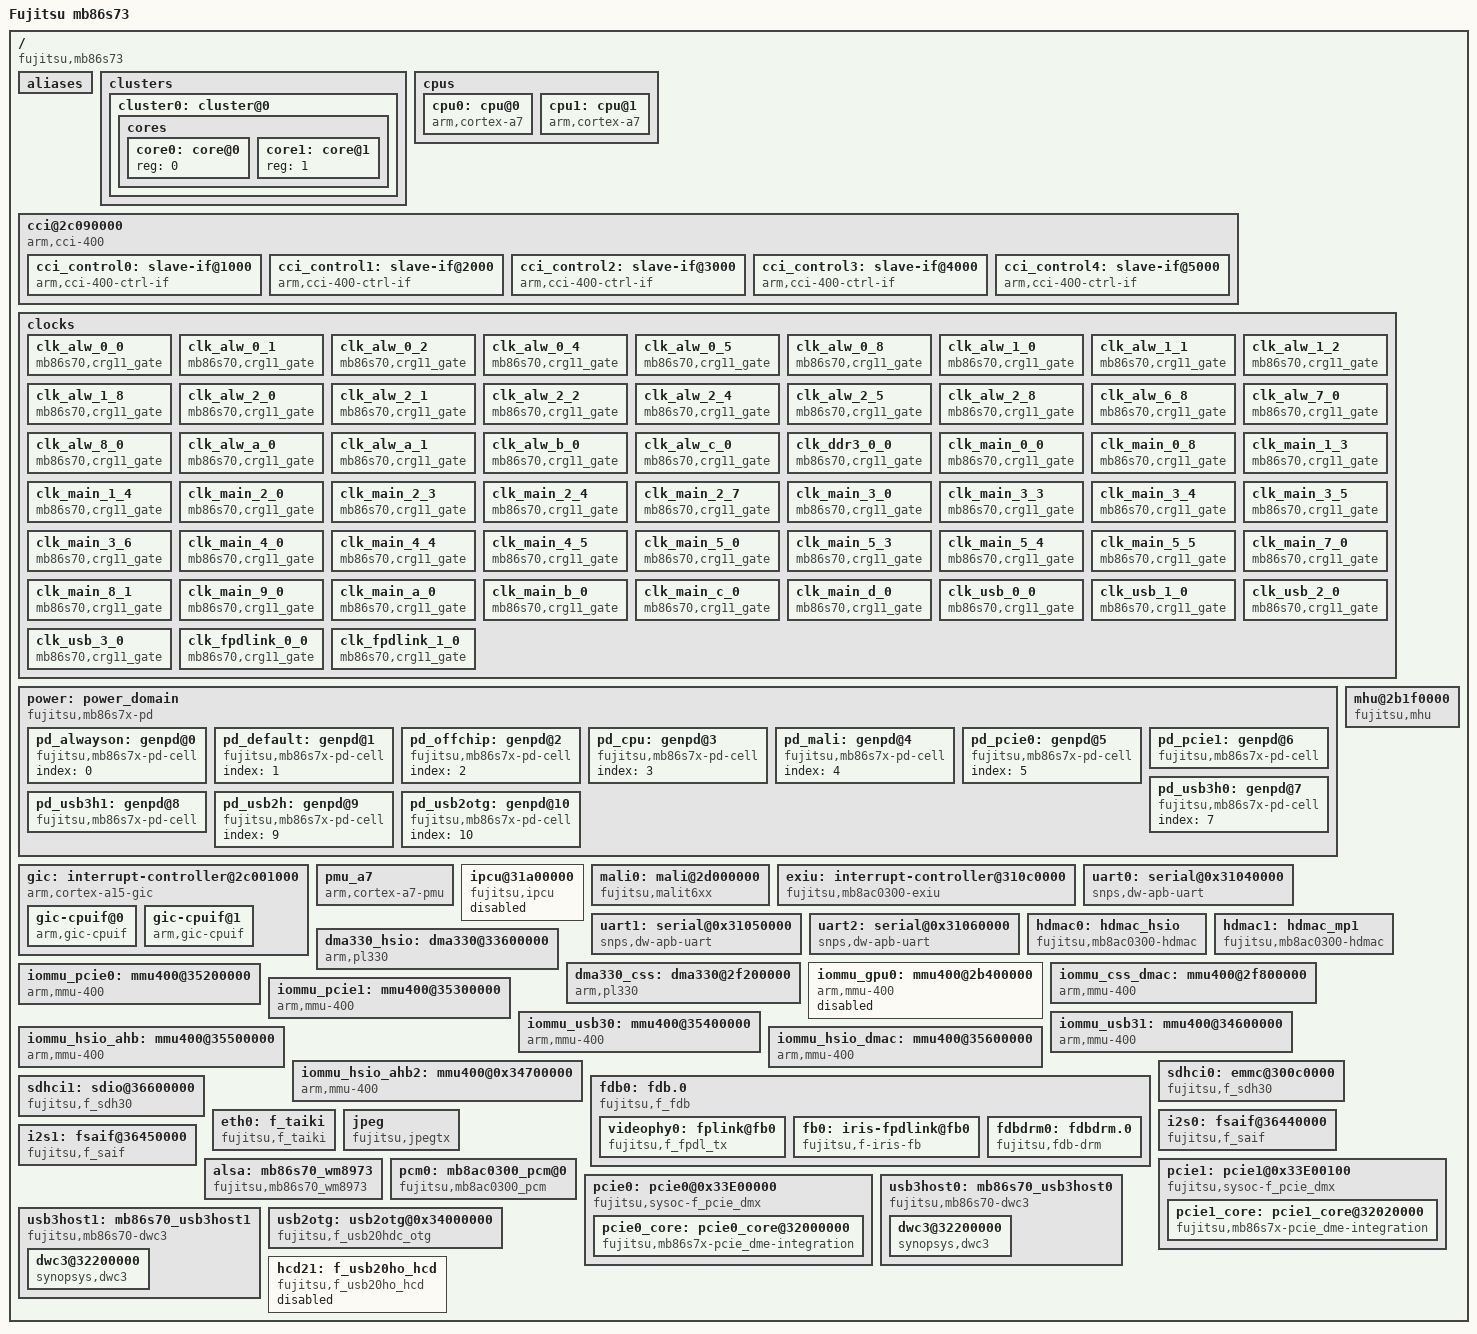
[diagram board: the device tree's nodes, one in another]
/*
 * Copyright (C) 2013-2015 Linaro, LTD for FUJITSU SEMICONDUCTOR LIMITED
 * Copyright (C) 2015-2016 Socionext Inc.
 *
 * This program is free software; you can redistribute it and/or modify
 * it under the terms of the GNU General Public License version 2 as
 * published by the Free Software Foundation.
 */

/ {
	model = "Fujitsu mb86s73";
	compatible = "fujitsu,mb86s73";
	interrupt-parent = <&gic>;
	#address-cells = <2>;
	#size-cells = <1>;

	aliases {
		serial0 = &uart0;
		serial1 = &uart1;
		serial2 = &uart2;
	};

	clusters {
		#address-cells = <1>;
		#size-cells = <0>;

		cluster0: cluster@0 {
			reg = <1>;
			freqs = <1200000000>;
			#gpio-cells = <2>;
			cores {
				#address-cells = <1>;
				#size-cells = <0>;
				#gpio-cells = <2>;
				core0: core@0 {
					reg = <0>;
				};

				core1: core@1 {
					reg = <1>;
				};
			};
		};
	};

	cpus {
		#address-cells = <1>;
		#size-cells = <0>;

		cpu0: cpu@0 {
			device_type = "cpu";
			compatible = "arm,cortex-a7";
			reg = <0x100>;
			cluster = <&cluster0>;
			core = <&core0>;
			clock-frequency = <1200000000>;
			cci-control-port = <&cci_control3>;
			operating-points = <
				/* kHz    uV */
				1200000  1040000
			>;
			clock-latency = <100000>;
			power-domains = <&power 3>;
		};

		cpu1: cpu@1 {
			device_type = "cpu";
			compatible = "arm,cortex-a7";
			reg = <0x101>;
			cluster = <&cluster0>;
			core = <&core1>;
			clock-frequency = <1200000000>;
			cci-control-port = <&cci_control3>;
			operating-points = <
				/* kHz    uV */
				1200000  1040000
			>;
			clock-latency = <100000>;
			power-domains = <&power 3>;
		};
	};

	cci@2c090000 {
		compatible = "arm,cci-400";
		#address-cells = <1>;
		#size-cells = <1>;
		reg = <0 0x2c090000 0x1000>;
		ranges = <0x0 0x0 0x2c090000 0x10000>;
		power-domains = <&power 2>;

		/* enable retention suspend semantics */
		retention-suspend;

		cci_control0: slave-if@1000 {
			compatible = "arm,cci-400-ctrl-if";
			interface-type = "ace-lite";
			reg = <0x1000 0x1000>;
		};

		cci_control1: slave-if@2000 {
			compatible = "arm,cci-400-ctrl-if";
			interface-type = "ace-lite";
			reg = <0x2000 0x1000>;
		};

		cci_control2: slave-if@3000 {
			compatible = "arm,cci-400-ctrl-if";
			interface-type = "ace-lite";
			reg = <0x3000 0x1000>;
		};

		cci_control3: slave-if@4000 {
			compatible = "arm,cci-400-ctrl-if";
			interface-type = "ace";
			reg = <0x4000 0x1000>;
		};

		cci_control4: slave-if@5000 {
 			compatible = "arm,cci-400-ctrl-if";
 			interface-type = "ace";
 			reg = <0x5000 0x1000>;
 		};
	};

	/**
	 * cntrlr : 0->ALW, 1->DDR3, 2->MAIN, 3->CA7, 4->USB, 5->FPDLINK
	 * port : [0,7] -> Gateable Clock Ports.  [8]->UngatedCLK
	 */
	clocks {
		clk_alw_0_0: clk_alw_0_0 {
			#clock-cells = <0>;
			compatible = "mb86s70,crg11_gate";
			cntrlr = <0>;
			domain = <0>;
			port = <0>;
		};
		clk_alw_0_1: clk_alw_0_1 {
			#clock-cells = <0>;
			compatible = "mb86s70,crg11_gate";
			cntrlr = <0>;
			domain = <0>;
			port = <1>;
		};
		clk_alw_0_2: clk_alw_0_2 {
			#clock-cells = <0>;
			compatible = "mb86s70,crg11_gate";
			cntrlr = <0>;
			domain = <0>;
			port = <2>;
		};
		clk_alw_0_4: clk_alw_0_4 {
			#clock-cells = <0>;
			compatible = "mb86s70,crg11_gate";
			cntrlr = <0>;
			domain = <0>;
			port = <4>;
		};
		clk_alw_0_5: clk_alw_0_5 {
			#clock-cells = <0>;
			compatible = "mb86s70,crg11_gate";
			cntrlr = <0>;
			domain = <0>;
			port = <5>;
		};
		clk_alw_0_8: clk_alw_0_8 {
			#clock-cells = <0>;
			compatible = "mb86s70,crg11_gate";
			cntrlr = <0>;
			domain = <0>;
			port = <8>;
		};

		clk_alw_1_0: clk_alw_1_0 {
			#clock-cells = <0>;
			compatible = "mb86s70,crg11_gate";
			cntrlr = <0>;
			domain = <1>;
			port = <0>;
		};
		clk_alw_1_1: clk_alw_1_1 {
			#clock-cells = <0>;
			compatible = "mb86s70,crg11_gate";
			cntrlr = <0>;
			domain = <1>;
			port = <1>;
		};
		clk_alw_1_2: clk_alw_1_2 {
			#clock-cells = <0>;
			compatible = "mb86s70,crg11_gate";
			cntrlr = <0>;
			domain = <1>;
			port = <2>;
		};
		clk_alw_1_8: clk_alw_1_8 {
			#clock-cells = <0>;
			compatible = "mb86s70,crg11_gate";
			cntrlr = <0>;
			domain = <1>;
			port = <8>;
		};
		clk_alw_2_0: clk_alw_2_0 {
			#clock-cells = <0>;
			compatible = "mb86s70,crg11_gate";
			cntrlr = <0>;
			domain = <2>;
			port = <0>;
		};
		clk_alw_2_1: clk_alw_2_1 {
			#clock-cells = <0>;
			compatible = "mb86s70,crg11_gate";
			cntrlr = <0>;
			domain = <2>;
			port = <1>;
		};
		clk_alw_2_2: clk_alw_2_2 {
			#clock-cells = <0>;
			compatible = "mb86s70,crg11_gate";
			cntrlr = <0>;
			domain = <2>;
			port = <2>;
		};
		clk_alw_2_4: clk_alw_2_4 {
			#clock-cells = <0>;
			compatible = "mb86s70,crg11_gate";
			cntrlr = <0>;
			domain = <2>;
			port = <4>;
		};
		clk_alw_2_5: clk_alw_2_5 {
			#clock-cells = <0>;
			compatible = "mb86s70,crg11_gate";
			cntrlr = <0>;
			domain = <2>;
			port = <5>;
		};
		clk_alw_2_8: clk_alw_2_8 {
			#clock-cells = <0>;
			compatible = "mb86s70,crg11_gate";
			cntrlr = <0>;
			domain = <2>;
			port = <8>;
		};
		clk_alw_6_8: clk_alw_6_8 {
			#clock-cells = <0>;
			compatible = "mb86s70,crg11_gate";
			cntrlr = <0>;
			domain = <6>;
			port = <8>;
		};

		clk_alw_7_0: clk_alw_7_0 {
			#clock-cells = <0>;
			compatible = "mb86s70,crg11_gate";
			cntrlr = <0>;
			domain = <7>;
			port = <0>;
		};
		clk_alw_8_0: clk_alw_8_0 {
			#clock-cells = <0>;
			compatible = "mb86s70,crg11_gate";
			cntrlr = <0>;
			domain = <8>;
			port = <0>;
		};
		clk_alw_a_0: clk_alw_a_0 {
			#clock-cells = <0>;
			compatible = "mb86s70,crg11_gate";
			cntrlr = <0>;
			domain = <0x0a>;
			port = <0>;
		};
		clk_alw_a_1: clk_alw_a_1 {
			#clock-cells = <0>;
			compatible = "mb86s70,crg11_gate";
			cntrlr = <0>;
			domain = <0x0a>;
			port = <1>;
		};
		clk_alw_b_0: clk_alw_b_0 {
			#clock-cells = <0>;
			compatible = "mb86s70,crg11_gate";
			cntrlr = <0>;
			domain = <0x0b>;
			port = <0>;
		};
		clk_alw_c_0: clk_alw_c_0 {
			#clock-cells = <0>;
			compatible = "mb86s70,crg11_gate";
			cntrlr = <0>;
			domain = <0x0c>;
			port = <0>;
		};
		clk_ddr3_0_0: clk_ddr3_0_0 {
			#clock-cells = <0>;
			compatible = "mb86s70,crg11_gate";
			cntrlr = <1>;
			domain = <0>;
			port = <0>;
		};

		clk_main_0_0: clk_main_0_0 {
			#clock-cells = <0>;
			compatible = "mb86s70,crg11_gate";
			cntrlr = <2>;
			domain = <0>;
			port = <0>;
		};
		clk_main_0_8: clk_main_0_8 {
			#clock-cells = <0>;
			compatible = "mb86s70,crg11_gate";
			cntrlr = <2>;
			domain = <0>;
			port = <8>;
		};
		clk_main_1_3: clk_main_1_3 {
			#clock-cells = <0>;
			compatible = "mb86s70,crg11_gate";
			cntrlr = <2>;
			domain = <1>;
			port = <3>;
		};
		clk_main_1_4: clk_main_1_4 {
			#clock-cells = <0>;
			compatible = "mb86s70,crg11_gate";
			cntrlr = <2>;
			domain = <1>;
			port = <4>;
		};
		clk_main_2_0: clk_main_2_0 {
			#clock-cells = <0>;
			compatible = "mb86s70,crg11_gate";
			cntrlr = <2>;
			domain = <2>;
			port = <0>;
		};
		clk_main_2_3: clk_main_2_3 {
			#clock-cells = <0>;
			compatible = "mb86s70,crg11_gate";
			cntrlr = <2>;
			domain = <2>;
			port = <3>;
		};
		clk_main_2_4: clk_main_2_4 {
			#clock-cells = <0>;
			compatible = "mb86s70,crg11_gate";
			cntrlr = <2>;
			domain = <2>;
			port = <4>;
		};

		clk_main_2_7: clk_main_2_7 {
			#clock-cells = <0>;
			compatible = "mb86s70,crg11_gate";
			cntrlr = <2>;
			domain = <2>;
			port = <7>;
		};
		clk_main_3_0: clk_main_3_0 {
			#clock-cells = <0>;
			compatible = "mb86s70,crg11_gate";
			cntrlr = <2>;
			domain = <3>;
			port = <0>;
		};
		clk_main_3_3: clk_main_3_3 {
			#clock-cells = <0>;
			compatible = "mb86s70,crg11_gate";
			cntrlr = <2>;
			domain = <3>;
			port = <3>;
		};
		clk_main_3_4: clk_main_3_4 {
			#clock-cells = <0>;
			compatible = "mb86s70,crg11_gate";
			cntrlr = <2>;
			domain = <3>;
			port = <4>;
		};
		clk_main_3_5: clk_main_3_5 {
			#clock-cells = <0>;
			compatible = "mb86s70,crg11_gate";
			cntrlr = <2>;
			domain = <3>;
			port = <5>;
		};
		clk_main_3_6: clk_main_3_6 {
			#clock-cells = <0>;
			compatible = "mb86s70,crg11_gate";
			cntrlr = <2>;
			domain = <3>;
			port = <6>;
		};
		clk_main_4_0: clk_main_4_0 {
			#clock-cells = <0>;
			compatible = "mb86s70,crg11_gate";
			cntrlr = <2>;
			domain = <4>;
			port = <0>;
		};
		clk_main_4_4: clk_main_4_4 {
			#clock-cells = <0>;
			compatible = "mb86s70,crg11_gate";
			cntrlr = <2>;
			domain = <4>;
			port = <4>;
		};
		clk_main_4_5: clk_main_4_5 {
			#clock-cells = <0>;
			compatible = "mb86s70,crg11_gate";
			cntrlr = <2>;
			domain = <4>;
			port = <5>;
		};

		clk_main_5_0: clk_main_5_0 {
			#clock-cells = <0>;
			compatible = "mb86s70,crg11_gate";
			cntrlr = <2>;
			domain = <5>;
			port = <0>;
		};
		clk_main_5_3: clk_main_5_3 {
			#clock-cells = <0>;
			compatible = "mb86s70,crg11_gate";
			cntrlr = <2>;
			domain = <5>;
			port = <3>;
		};
		clk_main_5_4: clk_main_5_4 {
			#clock-cells = <0>;
			compatible = "mb86s70,crg11_gate";
			cntrlr = <2>;
			domain = <5>;
			port = <4>;
		};
		clk_main_5_5: clk_main_5_5 {
			#clock-cells = <0>;
			compatible = "mb86s70,crg11_gate";
			cntrlr = <2>;
			domain = <5>;
			port = <5>;
		};
		clk_main_7_0: clk_main_7_0 {
			#clock-cells = <0>;
			compatible = "mb86s70,crg11_gate";
			cntrlr = <2>;
			domain = <7>;
			port = <0>;
		};
		clk_main_8_1: clk_main_8_1 {
			#clock-cells = <0>;
			compatible = "mb86s70,crg11_gate";
			cntrlr = <2>;
			domain = <8>;
			port = <1>;
		};
		clk_main_9_0: clk_main_9_0 {
			#clock-cells = <0>;
			compatible = "mb86s70,crg11_gate";
			cntrlr = <2>;
			domain = <9>;
			port = <0>;
		};
		clk_main_a_0: clk_main_a_0 {
			#clock-cells = <0>;
			compatible = "mb86s70,crg11_gate";
			cntrlr = <2>;
			domain = <0xa>;
			port = <0>;
		};
		clk_main_b_0: clk_main_b_0 {
			#clock-cells = <0>;
			compatible = "mb86s70,crg11_gate";
			cntrlr = <2>;
			domain = <0xb>;
			port = <0>;
		};
		clk_main_c_0: clk_main_c_0 {
			#clock-cells = <0>;
			compatible = "mb86s70,crg11_gate";
			cntrlr = <2>;
			domain = <0xc>;
			port = <0>;
		};
		clk_main_d_0: clk_main_d_0 {
			#clock-cells = <0>;
			compatible = "mb86s70,crg11_gate";
			cntrlr = <2>;
			domain = <0xd>;
			port = <0>;
		};

		clk_usb_0_0: clk_usb_0_0 {
			#clock-cells = <0>;
			compatible = "mb86s70,crg11_gate";
			cntrlr = <4>;
			domain = <0>;
			port = <0>;
		};
		clk_usb_1_0: clk_usb_1_0 {
			#clock-cells = <0>;
			compatible = "mb86s70,crg11_gate";
			cntrlr = <4>;
			domain = <1>;
			port = <0>;
		};
		clk_usb_2_0: clk_usb_2_0 {
			#clock-cells = <0>;
			compatible = "mb86s70,crg11_gate";
			cntrlr = <4>;
			domain = <2>;
			port = <0>;
		};
		clk_usb_3_0: clk_usb_3_0 {
			#clock-cells = <0>;
			compatible = "mb86s70,crg11_gate";
			cntrlr = <4>;
			domain = <3>;
			port = <0>;
		};

		clk_fpdlink_0_0: clk_fpdlink_0_0 {
			#clock-cells = <0>;
			compatible = "mb86s70,crg11_gate";
			cntrlr = <5>;
			domain = <0>;
			port = <0>;
		};
		clk_fpdlink_1_0: clk_fpdlink_1_0 {
			#clock-cells = <0>;
			compatible = "mb86s70,crg11_gate";
			cntrlr = <5>;
			domain = <1>;
			port = <0>;
		};
	};

	power: power_domain {
 		compatible = "fujitsu,mb86s7x-pd";
		#power-domain-cells = <1>;
		#address-cells = <2>;
		#size-cells = <1>;
		ranges;
 
		pd_alwayson: genpd@0 {
			compatible = "fujitsu,mb86s7x-pd-cell";
			index = <0>;
		};
		pd_default: genpd@1 {
			compatible = "fujitsu,mb86s7x-pd-cell";
			index = <1>;
		};
		pd_offchip: genpd@2 {
			compatible = "fujitsu,mb86s7x-pd-cell";
			index = <2>;
		};
		pd_cpu: genpd@3 {
			compatible = "fujitsu,mb86s7x-pd-cell";
			index = <3>;
		};
		pd_mali: genpd@4 {
			compatible = "fujitsu,mb86s7x-pd-cell";
			index = <4>;
		};
		pd_pcie0: genpd@5 {
			compatible = "fujitsu,mb86s7x-pd-cell";
			index = <5>;
		};
		pd_pcie1: genpd@6 {
			compatible = "fujitsu,mb86s7x-pd-cell";
			index = <6>;
			master-domain-cell = <&pd_pcie0>;
		};
		pd_usb3h0: genpd@7 {
			compatible = "fujitsu,mb86s7x-pd-cell";
			index = <7>;
		};
		pd_usb3h1: genpd@8 {
			compatible = "fujitsu,mb86s7x-pd-cell";
			index = <8>;
			/*
			 * here is a power domain dependency layout example.
			 * pd_usb3h1 will power-on index 7 then index 8.
			 */
			master-domain-cell = <&pd_usb3h0>;
		};
		pd_usb2h: genpd@9 {
			compatible = "fujitsu,mb86s7x-pd-cell";
			index = <9>;
		};
		pd_usb2otg: genpd@10 {
			compatible = "fujitsu,mb86s7x-pd-cell";
			index = <10>;
		};
	};

	gic: interrupt-controller@2c001000 {
		compatible = "arm,cortex-a15-gic", "arm,cortex-a9-gic";
		#interrupt-cells = <3>;
		interrupt-controller;
		reg = <0 0x2c001000 0x1000>,
		      <0 0x2c002000 0x1000>,
		      <0 0x2c004000 0x2000>,
		      <0 0x2c006000 0x2000>;
		interrupts = <1 9 0xf04>;
		#gpio-cells = <2>;

		gic-cpuif@0 {
			compatible = "arm,gic-cpuif";
			cpuif-id = <0>;
			cpu = <&cpu0>;
		};
		gic-cpuif@1 {
			compatible = "arm,gic-cpuif";
			cpuif-id = <1>;
			cpu = <&cpu1>;
		};
	};

	pmu_a7 {
		compatible = "arm,cortex-a7-pmu";
		cluster  = <&cluster0>;
		interrupts = <0 18 4>,
			     <0 22 4>;
		power-domains = <&power 1>;
	};

	ipcu@31a00000 {
		#clock-cells = <1>;
		compatible = "fujitsu,ipcu";
		status = "disabled";
		mboxes = <8>;
		reg = <0 0x31A00000 0x960>;
		interrupts = <0 152 4>, /* reserved */
			     <0 153 4>, /* reserved */
			     <0 154 4>, /* reserved */
			     <0 155 4>, /* reserved */
			     <0 156 4>, /* A7 CPU 0 */
			     <0 157 4>, /* A7 CPU 1 */
			     <0 158 4>, /* reserved */
			     <0 159 4>, /* reserved */
			     <0 160 4>; /* SCB */
		clocks = <&clk_alw_0_8>;
		power-domains = <&power 1>;
	};

	mhu@2b1f0000 {
		compatible = "fujitsu,mhu";
		reg = <0 0x2B1F0000 0x1000>;
		interrupts = <0 36 4>, /* LP Non-Sec */
			     <0 35 4>, /* HP Non-Sec */
			     <0 37 4>; /* Secure */
		clocks = <&clk_alw_0_8>;
		clock-names = "clk";
		power-domains = <&power 1>;
	};

	mali0: mali@2d000000 {
		compatible = "fujitsu,malit6xx";
		reg = <0 0x2d000000 0x10000>;
		interrupts = <0 33 4>, /* Mali JOB */
			<0 34 4>, /* Mali MMU */
			<0 32 4>; /* Mali GPU */
                interrupt-names = "JOB", "MMU", "GPU";
		clocks = <&clk_main_7_0>, <&clk_main_2_0>, <&clk_main_0_0>, <&clk_main_4_0>;
		clock-names = "g3d", "aclk_g3d", "mout_gpll", "fout_gpll";
		#stream-id-cells = <0>;
		power-domains = <&power 4>;
		cci-control-port = <&cci_control2>;
	};

	exiu: interrupt-controller@310c0000 {
		compatible = "fujitsu,mb8ac0300-exiu";
		reg = <0 0x310c0000 0x10000>;
		exiu_irq_base0 = <112>;
		exiu_irq_base1 = <128>;
		clocks = <&clk_alw_0_0>;
	};

	uart0: serial@0x31040000 {
		#clock-cells = <1>;
		compatible = "snps,dw-apb-uart";
		reg = <0 0x31040000 0x100>;
		interrupts = <0 320 0x4>;
		clock-frequency = <62500000>;
		reg-io-width = <4>;
		reg-shift = <2>;
		clocks = <&clk_alw_2_1>;
		clock-names = "sclk";
		power-domains = <&power 1>;
	};

	uart1: serial@0x31050000 {
		#clock-cells = <1>;
		compatible = "snps,dw-apb-uart";
		reg = <0 0x31050000 0x100>;
		interrupts = <0 321 0x4>;
		clock-frequency = <62500000>;
		reg-io-width = <4>;
		reg-shift = <2>;
		clocks = <&clk_alw_2_1>;
		clock-names = "sclk";
		power-domains = <&power 1>;
	};

	uart2: serial@0x31060000 {
		#clock-cells = <1>;
		compatible = "snps,dw-apb-uart";
		reg = <0 0x31060000 0x100>;
		interrupts = <0 322 0x4>;
		clock-frequency = <62500000>;
		reg-io-width = <4>;
		reg-shift = <2>;
		clocks = <&clk_alw_2_1>;
		clock-names = "sclk";
		power-domains = <&power 1>;
	};

	hdmac0: hdmac_hsio { /* USB2 */
		compatible = "fujitsu,mb8ac0300-hdmac";
		reg = <0 0x34080000 0x1000>;
		interrupts = <0 128 0x4>,
			     <0 129 0x4>;
		clocks = <&clk_alw_2_1>;
		channels = <2>;
		chip = <0>;
		rotation = <1>;
		power-domains = <&power 10>;
	};

	hdmac1: hdmac_mp1 { /* I2S */
		compatible = "fujitsu,mb8ac0300-hdmac";
		reg = <0 0x36400000 0x1000>;
		interrupts = <0 120 0x4>,
			     <0 121 0x4>,
			     <0 122 0x4>,
			     <0 123 0x4>;
		clocks = <&clk_main_3_6>;
		channels = <4>;
		chip = <1>;
		rotation = <1>;
	};

	dma330_hsio: dma330@33600000 {
		compatible = "arm,pl330", "arm,primecell";
		reg = <0 0x33600000 0x1000>;
		interrupts =    <0 144 4>,
				<0 145 4>,
				<0 146 4>,
				<0 147 4>;
		clocks = <&clk_main_0_8>;
		#stream-id-cells = <2>;
		iova-start = <0x00000000>;
		iova-range = <0x0 0x80000000>;
		clock-names = "apb_pclk";
		copy-align = <128>;
		#dma-cells = <1>;
		#dma-channels = <4>;
		#dma-requests = <1>;
		power-domains = <&power 2>;
	};

	dma330_css: dma330@2f200000 {
		compatible = "arm,pl330", "arm,primecell";
		reg = <0 0x2f200000 0x1000>;
		interrupts =    <0 136 4>,
				<0 137 4>,
				<0 138 4>,
				<0 139 4>,
				<0 140 4>,
				<0 141 4>,
				<0 142 4>,
				<0 143 4>;
		clocks = <&clk_main_0_8>;
		copy-align = <128>;
		clock-names = "apb_pclk";
		#stream-id-cells = <2>;
		iova-start = <0x00000000>;
		iova-range = <0x0 0x80000000>;
		#dma-cells = <1>;
		#dma-channels = <8>;
		#dma-requests = <32>;
		power-domains = <&power 2>;
	};

	iommu_gpu0: mmu400@2b400000 {
		status = "disabled";
		compatible = "arm,mmu-400";
		reg = <0 0x2b400000 0x10000>;
		#global-interrupts = <1>;
		interrupts = <0 39 4>, <0 38 4>;
		mmu-masters = <&mali0>;
		stream-ids = <0>;
		power-domains = <&power 4>;
	};
	iommu_css_dmac: mmu400@2f800000 {
		compatible = "arm,mmu-400";
		reg = <0 0x2f800000 0x10000>;
		#global-interrupts = <1>;
		interrupts = <0 64 4>, <0 65 4>;
		mmu-masters = <&dma330_css 0 1>;
		coherent_table_walk;
		stream-ids = <0>;
	};
	iommu_pcie0: mmu400@35200000 {
		compatible = "arm,mmu-400";
		reg = <0 0x35200000 0x10000>;
		#global-interrupts = <1>;
		interrupts = <0 71 4>, <0 70 4>;
		mmu-masters = <&pcie0 0 1>;
		stream-ids = <0>;
		power-domains = <&power 5>;
	};
	iommu_pcie1: mmu400@35300000 {
		compatible = "arm,mmu-400";
		reg = <0 0x35300000 0x10000>;
		#global-interrupts = <1>;
		interrupts = <0 73 4>, <0 72 4>;
		mmu-masters = <&pcie1 0 1>;
		stream-ids = <0>;
		power-domains = <&power 6>;
	};
	iommu_usb30: mmu400@35400000 {
		compatible = "arm,mmu-400";
		reg = <0 0x35400000 0x10000>;
		#global-interrupts = <1>;
		interrupts = <0 75 4>, <0 74 4>;
		mmu-masters = <&usb3host0 0 1>;
		stream-ids = <0>;
		power-domains = <&power 7>;
	};
	iommu_usb31: mmu400@34600000 {
		compatible = "arm,mmu-400";
		reg = <0 0x34600000 0x10000>;
		#global-interrupts = <1>;
		interrupts = <0 422 4>, <0 421 4>;
		mmu-masters = <&usb3host1 0 1>;
		stream-ids = <0>;
		power-domains = <&power 8>;
	};
	iommu_hsio_ahb: mmu400@35500000 {
		compatible = "arm,mmu-400";
		reg = <0 0x35500000 0x10000>;
		#global-interrupts = <1>;
		interrupts = <0 77 4>, <0 76 4>;
		mmu-masters = <&usb2otg 0 1>;
		stream-ids = <0>, <0>;
		power-domains = <&power 2>;
	};


	iommu_hsio_ahb2: mmu400@0x34700000 {
		compatible = "arm,mmu-400";
		reg = <0 0x34700000 0x10000>;
		#global-interrupts = <1>;
		interrupts = <0 77 4>, <0 76 4>;
		mmu-masters = <&hcd21 0 1>;
		stream-ids = <0>;
	};

	iommu_hsio_dmac: mmu400@35600000 {
		compatible = "arm,mmu-400";
		reg = <0 0x35600000 0x10000>;
		#global-interrupts = <1>;
		interrupts = <0 79 4>, <0 78 4>;
		mmu-masters = <&dma330_hsio 0 1>;
		stream-ids = <0>;
		power-domains = <&power 2>;
	};

	fdb0: fdb.0 {
		compatible = "fujitsu,f_fdb",
			     "simple-bus";

		id = <0>;
		#stream-id-cells = <2>;
		iova-start = <0x90000000>;
		iova-range = <0x0 0x50000000>;
		#address-cells = <2>;
		#size-cells = <1>;
		ranges;

		/* fpdlink */
		videophy0: fplink@fb0 {
			compatible = "fujitsu,f_fpdl_tx";
			reg = <0 0x37300000 0x8000>;
			selmap = <1>;
			interrupts = <0 144 0x4>; /* lock interrupt */
			sources = <1>; /* bitfield of fbs can be driven by */
			clocks = <&clk_fpdlink_0_0>, <&clk_fpdlink_1_0>, <&clk_main_3_0>, <&clk_main_5_0>;
			clock-names = "pllclk", "dpiclk", "pclk", "clk4";
			power-domains = <&power 2>;
			simple-bind = <&fb0>;
		};

		/* FPDLINK IRIS */
		fb0: iris-fpdlink@fb0 {
			compatible = "fujitsu,f-iris-fb";
			reg = <0 0x37050000 0x8000>;
			interrupts = <0 384 0x4>,
				     <0 385 0x4>,
				     <0 386 0x4>,
				     <0 387 0x4>,
				     <0 388 0x4>,
				     <0 389 0x4>,
				     <0 390 0x4>,
				     <0 391 0x4>,
				     <0 392 0x4>,
				     <0 393 0x4>,
				     <0 394 0x4>,
				     <0 395 0x4>,
				     <0 396 0x4>,
				     <0 397 0x4>,
				     <0 398 0x4>,
				     <0 399 0x4>;
			id = <0>;
			simple = <0>;
			perf-mode = <1>;
			/* EVB LCD timings / resolution */
			mode = "800x480x32bpp";
			clocks = <&clk_fpdlink_0_0>, <&clk_main_a_0>, <&clk_main_b_0>;
			clock-names = "clk1", "clk2", "clk3";
			power-domains = <&power 2>;
		};

		fdbdrm0: fdbdrm.0 {
			status = "okay";
			compatible = "fujitsu,fdb-drm";
			bind = <&fb0>;
			registrations = <2>; /* wait for this many children */
			default-bpp = <32>; /* set to 16 if 16-bit LCD mode selected */

		};
	};

	sdhci0: emmc@300c0000 {
		compatible = "fujitsu,f_sdh30";
		reg = <0 0x300c0000 0x1000>;
		interrupts = <0 164 0x4>,
			     <0 165 0x4>;
		resume-detect-retry;
		mmc-caps2 = <0x20>;
		vendor-hs200 = <0x01000000>;
		bus-width = <8>;
		tuning_count_default = <0xA>;
		/* clocks = <&clk_alw_c_0>, <&clk_alw_b_0>; */
		/* clock-names = "sd_sd4clk", "sd_bclk"; */
		power-domains = <&power 1>;
	};

	sdhci1: sdio@36600000 {
		compatible = "fujitsu,f_sdh30";
		reg = <0 0x36600000 0x1000>;
		interrupts = <0 172 0x4>,
			     <0 173 0x4>;
		resume-detect-retry;
		tuning_count_default = <0xA>;
		/* clocks = <&clk_main_c_0>, <&clk_main_d_0>; */
		/* clock-names = "sd_sd4clk", "sd_bclk"; */
		#stream-id-cells = <2>;
		iova-start = <0x90000000>;
		iova-range = <0x0 0x50000000>;
		power-domains = <&power 2>;
	};

	eth0: f_taiki {
                compatible = "fujitsu,f_taiki";
                id = <0>;
                default_mac = < 0xa4 0x17 0x31 0x73 0x00 0xed >;
		reg = <0 0x31600000 0x10000>;
		interrupts = <0 163 0x4>;
		/* fake clocks */
		clocks = <&clk_alw_0_8>, <&clk_alw_0_8>, <&clk_alw_0_8>;
		clock-names = "h_clk", "osc_clk", "pclk";
		phy-interface = "RGMII";
		phy-dev-addr = <1>;
		phy-status-poll-interval-ms = <500>;
		link-speed = "1G";
		half-duplex = <0>;
		flow-control = <1>;
		use-jumbo = <1>;
		gpio-phy-enable = <14>; /* !!! correct when S73 EVB schematics available */
		gpio-phy-nrst = <13>; /* !!! correct when S73 EVB schematics available */
		power-domains = <&power 1>;
	};


	jpeg: jpeg {
		compatible = "fujitsu,jpegtx";

		reg = <0 0x36020000 0x10000>;
		id = <0>;
		interrupts = <0 190 0x4>;
		clocks = <&clk_main_5_5>, <&clk_main_8_1>;
		clock-names = "clk1", "clk2";
		memory-size = <0x01000000>; /* 16MB */
		#stream-id-cells = <2>;
		iova-start = <0x90000000>;
		iova-range = <0x0 0x50000000>;
		fujitsu,power-domain = <&pd_offchip>;
		power-domains = <&power 2>;
	};

	i2s0: fsaif@36440000 {
		compatible = "fujitsu,f_saif";

		reg = <0 0x36440000 0x1000>;
		interrupts = <0 180 0x4>;
		clocks = <&clk_main_3_6>;
		power-domains = <&power 2>;
	};

	i2s1: fsaif@36450000 {
		compatible = "fujitsu,f_saif";

		reg = <0 0x36450000 0x1000>;
		interrupts = <0 181 0x4>;
		clocks = <&clk_main_3_6>;
		power-domains = <&power 2>;
	};

	alsa: mb86s70_wm8973 {
		compatible = "fujitsu,mb86s70_wm8973";
		reg = <0 0 0>; /* fake to stop xx.123 disease */
		channel = <0>;
		ms_mode = <0x4000>; // SND_SOC_DAIFMT_CBS_CFS
		format = <1>; // SND_SOC_DAIFMT_I2S
		use_eclk = <1>; // 0 = AHB
		#stream-id-cells = <2>;
		iova-start = <0x90000000>;
		iova-range = <0x0 0x50000000>;
	};

	pcm0: mb8ac0300_pcm@0 {
		compatible = "fujitsu,mb8ac0300_pcm";
		reg = <0 0 0>; /* fake to stop xx.123 disease */
		/* which hdmac chip we are hooked to */
		hdmac = <1>;
		/* which periperhal dma request lines we are hooked to */
		hdmac-trig-pid-capture =  <0x11000000>; /* HDMACA_IS_IDREQ1H */
		hdmac-trig-pid-playback = <0x12000000>; /* HDMACA_IS_IDREQ2H */
		power-domains = <&power 1>;
	};

	pcie1:pcie1@0x33E00100 {
		compatible = "fujitsu,sysoc-f_pcie_dmx";
		#address-cells = <2>;
		#size-cells = <1>;
		id = <1>;
		ranges;
		reg = <0 0x33E00100 0x64>;
		clock_num = <1>;
		clock-names = "pcie1_hclk";
		clocks = <&clk_alw_2_2>;
		phy_reset;
		#stream-id-cells = <2>;
		iova-start = <0x00000000>;
		iova-range = <0x1 0x00000000>;
		power-domains = <&power 6>;

		pcie1_core: pcie1_core@32020000 {
			compatible = "fujitsu,mb86s7x-pcie_dme-integration";
			ven_dev_id = <0x10cf 0x2046>;
			/* enable msi */
			reg = <0 0x32020000 0x20000>, <0 0x320e0000 0x1000>, <0 0x320e1200 0x1000>;
			/* disable msi */
			/* reg = <0 0x32020000 0x20000>, <0 0x320e0000 0x1000>; */
			interrupts = <0 260 4>, <0 261 4>, <0 262 4>, <0 263 4>,
						<0 264 4>, <0 267 4>,<0 269 4>, <0 270 4>,
						<0 271 4>, <0 272 4>, <0 411 4>;
			dma_int_off = <6>;
			pme_int_off = <4>;
			/* 0: INTx, 1:MSI, 2:MSI-X */
			int_type = <1>;
			/* 0: 1_type, 1: 2_type, 2: 4_type ...  5: 32_type */
			msi-multi = <0>;
			clocks = <&clk_alw_0_0>,<&clk_alw_0_2>,<&clk_alw_2_0>;
			clock-names = "bus_pcie_aclk","pcie1_aclk","pcie_pclk";
			clock_num = <3>;
			link_spd = <1>; /* 0=>2.5GT/s, 1=>2.5GT/s and 5.0GT/s */
			link_wid = <4>; /* 1=> max land x1, 4=> max land x4 */
			#address-cells = <3>;
			#size-cells = <2>;
			ranges = <0x41000000 0x0 0x00000000 0x0 0x58000000 0 0x08000000
					0x02000000 0x0 0x00000000 0x0 0x70000000 0 0x04000000
					0x02000000 0x0 0x04000000 0x0 0x74000000 0 0x04000000
					0x02000000 0x0 0x08000000 0x0 0x78000000 0 0x04000000
					0x02000000 0x0 0x0C000000 0x0 0x7C000000 0 0x02000000
					0x03000000 0x0 0x40000000 0x6 0x40000000 0 0x40000000
					0x03000000 0x0 0x80000000 0x6 0x80000000 0 0x40000000
					0x00000000 0x0 0xC0000000 0x0 0x32060000 0 0x00010000>;
	
//				pinctrl-names = "default", "sleep";
//				pinctrl-0 = <&pcie1_pins_active>;
//				pinctrl-1 = <&pcie1_pins_sleep>;
		};
	};

	pcie0:pcie0@0x33E00000 {
		compatible = "fujitsu,sysoc-f_pcie_dmx";
		#address-cells = <2>;
		#size-cells = <1>;
		id = <0>;
		ranges;
		reg = <0 0x33E00000 0x64>;
		clock_num = <1>;
		clock-names = "pcie0_hclk";
		clocks = <&clk_alw_2_1>;
		phy_reset;
		#stream-id-cells = <2>;
		iova-start = <0x00000000>;
		iova-range = <0x1 0x00000000>;
		power-domains = <&power 5>;

		pcie0_core: pcie0_core@32000000 {
			compatible = "fujitsu,mb86s7x-pcie_dme-integration";
			/* enable msi */
			reg = <0 0x32000000 0x20000>, <0 0x320a0000 0x1000>, <0 0x320a1200 0x1000>;
			/* disable msi */
			/* reg = <0 0x32000000 0x20000>, <0 0x320a0000 0x1000>/*,<0 0x320a1200 0x1000>; */
			interrupts = <0 240 4>, <0 241 4>, <0 242 4>, <0 243 4>,
						<0 244 4>, <0 247 4>, <0 249 4>, <0 250 4>,
						<0 251 4>, <0 252 4>, <0 407 4>;
			dma_int_off = <6>;
			pme_int_off = <4>;
			/* 0: 1_type, 1: 2_type, 2: 4_type ...  5: 32_type */
			msi-multi = <0>;
			clocks = <&clk_alw_0_0>,<&clk_alw_0_1>,<&clk_alw_2_0>;
			clock-names = "bus_pcie_aclk","pcie0_aclk","pcie_pclk";
			clock_num = <3>;
			link_spd = <1>; /* 0=>2.5GT/s, 1=>2.5GT/s and 5.0GT/s */
			link_wid = <4>; /* 1=> max land x1, 4=> max land x4 */
			/* ranges = <phys.hi phys.mid phys.low cpu range */
			#address-cells = <3>;
			#size-cells = <2>;
			ranges = <0x41000000 0x0 0x00000000 0x0 0x50000000 0 0x08000000
					0x02000000 0x0 0x00000000 0x0 0x60000000 0 0x04000000
					0x02000000 0x0 0x02000000 0x0 0x64000000 0 0x04000000
					0x02000000 0x0 0x08000000 0x0 0x68000000 0 0x04000000
					0x02000000 0x0 0x0C000000 0x0 0x6C000000 0 0x04000000
					0x03000000 0x0 0x40000000 0x4 0x40000000 0 0x40000000
					0x03000000 0x0 0x80000000 0x4 0x80000000 0 0x40000000
					0x00000000 0x0 0xC0000000 0x0 0x32040000 0 0x00010000>;
	
//			pinctrl-names = "default", "sleep";
//			pinctrl-0 = <&pcie0_pins_active>;
//			pinctrl-1 = <&pcie0_pins_sleep>;
		};
	};

	usb3host0: mb86s70_usb3host0 {
		compatible = "fujitsu,mb86s70-dwc3";
		reg = <0 0x32200000 0x100000>;
		clocks = <&clk_alw_1_1>;
		clock-names = "h_clk";
		#address-cells = <2>;
		#size-cells = <1>;
		ranges;
		#stream-id-cells = <2>;
		iova-start = <0x00000000>;
		iova-range = <0x1 0x00000000>;
		power-domains = <&power 7>;

		dwc3@32200000 {
			compatible = "synopsys,dwc3";
			reg = <0 0x32200000 0x100000>;
			interrupts = <0 292 0x4>,
			             <0 294 0x4>;
			disconnection-quirk;
		};
	};

	usb3host1: mb86s70_usb3host1 {
		compatible = "fujitsu,mb86s70-dwc3";
		reg = <0 0x32300000 0x100000>;
		clocks = <&clk_alw_1_2>;
		clock-names = "h_clk";
		#address-cells = <2>;
		#size-cells = <1>;
		ranges;
		#stream-id-cells = <2>;
		iova-start = <0x00000000>;
		iova-range = <0x1 0x00000000>;
		power-domains = <&power 8>;

		dwc3@32200000 {
			compatible = "synopsys,dwc3";
			reg = <0 0x32300000 0x100000>;
			interrupts = <0 412 0x4>,
			             <0 414 0x4>;
			disconnection-quirk;
		};
	};

	usb2otg: usb2otg@0x34000000 {
		compatible = "fujitsu,f_usb20hdc_otg";
		reg = <0 0x34000000 0x10000>;
		interrupts = <0 296 0x4>;
		dma_dreq = <0x0e000000 0x0e000000>;
		hdmac_channel = <0 1>;
		clocks = <&clk_main_2_3>, <&clk_main_4_4>, <&clk_usb_1_0>;
		clock-names = "h_clk", "p_clk", "p_cryclk";
		#stream-id-cells = <2>;
		iova-start = <0x00000000>;
		iova-range = <0x1 0x00000000>;
		power-domains = <&power 10>;
	};

	hcd21: f_usb20ho_hcd {
		status = "disabled";
		compatible = "fujitsu,f_usb20ho_hcd";
		reg = <0 0x34200000 0x80000>;
		interrupts = <0 419 0x4>;
		clocks = <&clk_main_2_4>, <&clk_main_4_5>, <&clk_usb_0_0>;
		clock-names = "h_clk", "p_clk", "p_cryclk";
		#stream-id-cells = <2>;
		iova-start = <0x00000000>;
		iova-range = <0x1 0x00000000>;
		power-domains = <&power 9>;
	};
};
